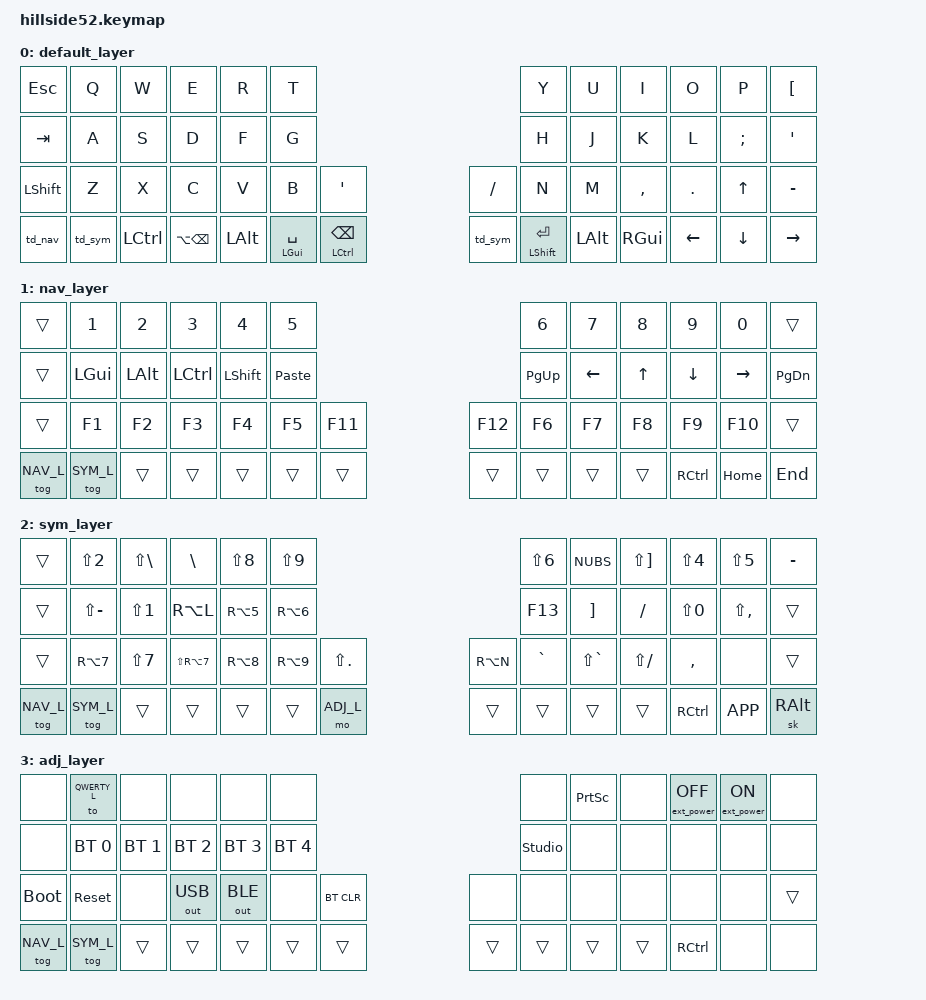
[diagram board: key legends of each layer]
/*
 * Copyright (c) 2021-2022 The ZMK Contributors
 *
 * SPDX-License-Identifier: MIT
 */

#include <behaviors.dtsi>
#include <dt-bindings/zmk/bt.h>
#include <dt-bindings/zmk/ext_power.h>
#include <dt-bindings/zmk/keys.h>
#include <dt-bindings/zmk/outputs.h>

#define QWERTY_L 0
#define NAV_L    1
#define SYM_L    2
#define ADJ_L    3

#define Undo   LC(Z)
#define Cut    LC(X)
#define Copy   LC(C)
#define Paste  LC(V)
#define Redo   LC(Y)


/ {
        behaviors {
                td_nav: td_nav {
                        compatible = "zmk,behavior-tap-dance";
                        #binding-cells = <0>;
                        tapping-term-ms = <220>;
                        bindings = <&mo NAV_L>, <&tog NAV_L>;
                };

                td_sym: td_sym {
                        compatible = "zmk,behavior-tap-dance";
                        #binding-cells = <0>;
                        tapping-term-ms = <220>;
                        bindings = <&mo SYM_L>, <&tog SYM_L>;
                };

                mt_gui_spc: mt_gui_spc {
                        compatible = "zmk,behavior-hold-tap";
                        #binding-cells = <2>;
                        flavor = "balanced";
                        tapping-term-ms = <220>;
                        bindings = <&kp>, <&kp>;
                };
                mt_lctrl_bspc: mt_lctrl_bspc {
                        compatible = "zmk,behavior-hold-tap";
                        #binding-cells = <2>;
                        flavor = "balanced";
                        tapping-term-ms = <220>;
                        bindings = <&kp>, <&kp>;
                };

                mt_gui_bspc: mt_gui_bspc {
                        compatible = "zmk,behavior-hold-tap";
                        #binding-cells = <2>;
                        flavor = "balanced";
                        tapping-term-ms = <220>;
                        bindings = <&kp>, <&kp>;
                };

                mt_shift_enter: mt_shift_enter {
                        compatible = "zmk,behavior-hold-tap";
                        #binding-cells = <2>;
                        flavor = "balanced";
                        tapping-term-ms = <220>;
                        bindings = <&kp>, <&kp>;
                };

        };

        keymap {
                compatible = "zmk,keymap";

                default_layer {
/* QWERTZ
 * -------------------------------------------------------------------------------------------------------------------------------------
 * | ESC   |   Q   |   W   |   E   |   R   |   T   |-----------------------------------|   Y   |   U   |   I   |   O   |   P    |  Ü     |
 * | TAB   |   A   |   S   |   D   |   F   |   G   |-----------------------------------|   H   |   J   |   K   |   L   |   Ö    |   Ä    |
 * | SHIFT |   Z   |   X   |   C   |   V   |   B   |   '   |-------------------|   /   |   N   |   M   |   ,   |   .   |  Up    | MINUS  |
 * | NAV   |  SYM  | CTRL  |-------|ALT+BSP|  ALT  |CMD SPACE|  CTRL BSPC   |---| SYM_L | ENTER |  ALT  |  GUI  |-------| Left   | Down   | Right |
 */
                        bindings = <
&kp  ESC      &kp  Q        &kp  W        &kp  E        &kp  R        &kp  T                                                                         &kp  Y        &kp  U        &kp  I        &kp  O        &kp  P       &kp  LBKT
&kp  TAB      &kp  A        &kp  S        &kp  D        &kp  F        &kp  G                                                                         &kp  H        &kp  J        &kp  K        &kp  L        &kp  SEMI    &kp  SQT
&kp  LSHFT    &kp  Z        &kp  X        &kp  C        &kp  V        &kp  B        &kp  SQT                                           &kp  SLASH    &kp  N        &kp  M        &kp  COMMA    &kp  DOT      &kp  UP      &kp  MINUS
&td_nav       &td_sym       &kp  LCTRL                  &kp  LA(BSPC) &kp  LALT     &mt_gui_spc  LGUI SPACE    &mt_lctrl_bspc  LCTRL BSPC    &td_sym       &mt_shift_enter  LSHIFT ENTER  &kp LALT &kp  RGUI                   &kp LEFT      &kp DOWN     &kp  RIGHT
                        >;
			
                };

                nav_layer {
/* NAV
 * -------------------------------------------------------------------------------------------------------------------------------------
 * | TRNS  |   1   |   2   |   3   |   4   |   5   |-----------------------------------|   6   |   7   |   8   |   9   |   0   | TRNS  |
 * | TRNS  |  GUI  |  Alt  | Ctrl  | Shift | Paste |-----------------------------------| PG UP |  Left |  Up   |  Down | Right | PG DN |
 * | TRNS  |  F1   |  F2   |  F3   |  F4   |  F5   |  F11  |-------------------| F12   |  F6   |  F7   |  F8   |  F9   |  F10  | TRNS  |
 * |NAV/TOG|SYM/TOG| TRNS  |-------| TRNS  | TRNS  | TRNS  | TRNS  |---| TRNS  | TRNS  | TRNS  | TRNS  |-------| RCTRL | HOME  | END   |
 */
                        bindings = <
&trans        &kp  N1       &kp  N2       &kp  N3       &kp  N4       &kp  N5                                                                        &kp   N6      &kp  N7      &kp   N8      &kp   N9      &kp  N0       &trans
&trans        &kp  LGUI     &kp  LALT     &kp  LCTRL    &kp  LSHFT    &kp  Paste                                                                     &kp   PG_UP   &kp  LEFT    &kp   UP      &kp   DOWN    &kp  RIGHT    &kp PG_DN
&trans        &kp  F1       &kp  F2       &kp  F3       &kp  F4       &kp  F5       &kp F11                                            &kp  F12      &kp   F6      &kp  F7      &kp   F8      &kp   F9      &kp  F10      &trans
&tog  NAV_L   &tog  SYM_L   &trans                      &trans        &trans        &trans        &trans                 &trans        &trans        &trans        &trans                     &kp  RCTRL    &kp  HOME     &kp  END
                        >;
			
                };

                sym_layer {
/* SYM
 * -------------------------------------------------------------------------------------------------------------------------------------
 * | TRNS  |   "   |   '   |   #   |   (   |   )   |-----------------------------------|   &   |   ^   |   *   |   $   |   %   | ? / ß|
 * | TRNS  |   ?   |   !   |   @   |   [   |   ]   |-----------------------------------|   `   |   +   |   -   |   =   |   ;   | TRNS |
 * | TRNS  |   |   |   /   |   \   |   {   |   }   |   :   |-------------------|   ~   |   <   |   >   |   _   |   ,   | TRNS  | NONE |
 * |NAV/TOG|SYM/TOG| TRNS  |-------| TRNS  | TRNS  | TRNS  | TRNS  |----| TRNS | TRNS  | TRNS  | TRNS  |-------| TRNS  | TRNS  | TRNS |
 */
                        bindings = <
&trans        &kp  LS(N2)   &kp  LS(BSLH) &kp  BSLH     &kp  LS(N8)   &kp  LS(N9)                                                                         &kp  LS(N6)   &kp  NUBS     &kp  LS(RBKT) &kp  LS(N4)   &kp  LS(N5)   &kp  MINUS
&trans        &kp  LS(MINUS)&kp  LS(N1)   &kp  RA(L)    &kp  RA(N5)   &kp  RA(N6)                                                                         &kp  F13      &kp  RBKT     &kp  SLASH    &kp  LS(N0)   &kp  LS(COMMA)&trans
&trans        &kp  RA(N7)   &kp  LS(N7)   &kp  LS(RA(N7))&kp  RA(N8)   &kp  RA(N9)   &kp  LS(DOT)                                       &kp  RA(N)    &kp  GRAVE    &kp  LS(GRAVE)&kp  LS(SLASH)&kp  COMMA    &none         &trans
&tog  NAV_L   &tog  SYM_L        &trans                      &trans        &trans        &trans        &mo  ADJ_L               &trans      &trans        &trans        &trans                      &kp  RCTRL    &kp  K_APP    &sk  RALT
                        >;
			
                };
		

                adj_layer {
/* ADJUST
 * -------------------------------------------------------------------------------------------------------------------------------------
 * |       | QWERTY|       |       |       |       |-----------------------------------|       |Prt Scr|       | EP_OFF| EP_ON |       |
 * |       | BT 0  | BT 1  | BT 2  | BT 3  | BT 4  |-----------------------------------| STUDIO|       |       |       |       |       |
 * | BOOTL | RESET | NONE  |OUT_USB|OUT_BLE| NONE  |BT CLR |-------------------| NONE  | NONE  | NONE  | NONE  | NONE  | NONE  | TRNS  |
 * | NONE  | NONE  | TRNS  |-------| TRNS  | TRNS  | TRNS  | TRNS  |---| TRNS  | TRNS  | TRNS  | TRNS  |-------| RCTRL | NONE  | NONE  |
 */
                        bindings = <
&none         &to  QWERTY_L &none         &none         &none         &none                                                                             &none             &kp PRINTSCREEN    &none         &ext_power EP_OFF  &ext_power EP_ON &none
&none         &bt  BT_SEL 0 &bt  BT_SEL 1 &bt  BT_SEL 2 &bt  BT_SEL 3 &bt  BT_SEL 4                                                                     &studio_unlock    &none              &none            &none           &none            &none
&bootloader   &sys_reset    &none         &out OUT_USB  &out OUT_BLE  &none         &bt BT_CLR                                         &none            &none             &none              &none            &none           &none            &trans
&tog  NAV_L   &tog  SYM_L   &trans                      &trans        &trans        &trans        &trans                 &trans        &trans           &trans            &trans                              &kp  RCTRL      &none            &none
                        >;
			
                };
        };
};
